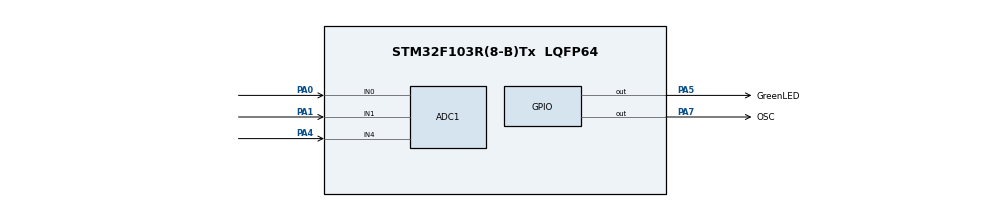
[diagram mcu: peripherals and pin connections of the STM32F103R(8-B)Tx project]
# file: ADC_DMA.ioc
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ADC1.Channel-0\#ChannelRegularConversion=ADC_CHANNEL_0
ADC1.Channel-1\#ChannelRegularConversion=ADC_CHANNEL_1
ADC1.Channel-2\#ChannelRegularConversion=ADC_CHANNEL_4
ADC1.ContinuousConvMode=ENABLE
ADC1.NbrOfConversion=3
ADC1.NbrOfConversionFlag=1
ADC1.Rank-0\#ChannelRegularConversion=1
ADC1.Rank-1\#ChannelRegularConversion=2
ADC1.Rank-2\#ChannelRegularConversion=3
ADC1.SamplingTime-0\#ChannelRegularConversion=ADC_SAMPLETIME_239CYCLES_5
ADC1.SamplingTime-1\#ChannelRegularConversion=ADC_SAMPLETIME_239CYCLES_5
ADC1.SamplingTime-2\#ChannelRegularConversion=ADC_SAMPLETIME_239CYCLES_5
ADC1.master=1
Dma.ADC1.0.Direction=DMA_PERIPH_TO_MEMORY
Dma.ADC1.0.Instance=DMA1_Channel1
Dma.ADC1.0.MemDataAlignment=DMA_MDATAALIGN_HALFWORD
Dma.ADC1.0.MemInc=DMA_MINC_ENABLE
Dma.ADC1.0.Mode=DMA_CIRCULAR
Dma.ADC1.0.PeriphDataAlignment=DMA_PDATAALIGN_HALFWORD
Dma.ADC1.0.PeriphInc=DMA_PINC_DISABLE
Dma.ADC1.0.Priority=DMA_PRIORITY_LOW
Dma.Request0=ADC1
Mcu.Family=STM32F1
Mcu.Name=STM32F103R(8-B)Tx
Mcu.Package=LQFP64
NVIC.DMA1_Channel1_IRQn=true\:0\:0\:false\:false\:true\:false\:true\:true
NVIC.PriorityGroup=NVIC_PRIORITYGROUP_4
PA0-WKUP.Signal=ADCx_IN0
PA1.Signal=ADCx_IN1
PA4.Signal=ADCx_IN4
PA5.GPIO_Label=GreenLED
PA5.Signal=GPIO_Output
PA7.GPIO_Label=OSC
PA7.Signal=GPIO_Output
ProjectManager.HeapSize=0x200
ProjectManager.StackSize=0x400
ProjectManager.TargetToolchain=MDK-ARM V5.32
RCC.APB1Freq_Value=8000000
RCC.APB2Freq_Value=8000000
SH.ADCx_IN0.0=ADC1_IN0,IN0
SH.ADCx_IN1.0=ADC1_IN1,IN1
SH.ADCx_IN4.0=ADC1_IN4,IN4
VP_SYS_VS_ND.Mode=No_Debug
board=custom

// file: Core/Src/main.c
/* USER CODE BEGIN Header */
/**
  ******************************************************************************
  * @file           : main.c
  * @brief          : Main program body
  ******************************************************************************
  * @attention
  *
  * Copyright (c) 2024 STMicroelectronics.
  * All rights reserved.
  *
  * This software is licensed under terms that can be found in the LICENSE file
  * in the root directory of this software component.
  * If no LICENSE file comes with this software, it is provided AS-IS.
  *
  ******************************************************************************
  */
/* USER CODE END Header */
#include "main.h"

ADC_HandleTypeDef hadc1;
DMA_HandleTypeDef hdma_adc1;

/* USER CODE BEGIN PV */

uint16_t AdcValueArray[3];

/* USER CODE END PV */

void SystemClock_Config(void);
static void MX_GPIO_Init(void);
static void MX_DMA_Init(void);
static void MX_ADC1_Init(void);

int main(void)
{

  /* MCU Configuration--------------------------------------------------------*/

  /* Reset of all peripherals, Initializes the Flash interface and the Systick. */
  HAL_Init();

  /* Configure the system clock */
  SystemClock_Config();

  /* Initialize all configured peripherals */
  MX_GPIO_Init();
  MX_DMA_Init();
  MX_ADC1_Init();
  /* USER CODE BEGIN 2 */

	HAL_ADC_Start_DMA(&hadc1, (uint32_t*) AdcValueArray, 3);

  /* USER CODE END 2 */

  /* Infinite loop */
  while (1)
  {

  }
}

void SystemClock_Config(void)
{
  RCC_OscInitTypeDef RCC_OscInitStruct = {0};
  RCC_ClkInitTypeDef RCC_ClkInitStruct = {0};
  RCC_PeriphCLKInitTypeDef PeriphClkInit = {0};

  /** Initializes the RCC Oscillators according to the specified parameters
  * in the RCC_OscInitTypeDef structure.
  */
  RCC_OscInitStruct.OscillatorType = RCC_OSCILLATORTYPE_HSI;
  RCC_OscInitStruct.HSIState = RCC_HSI_ON;
  RCC_OscInitStruct.HSICalibrationValue = RCC_HSICALIBRATION_DEFAULT;
  RCC_OscInitStruct.PLL.PLLState = RCC_PLL_NONE;
  if (HAL_RCC_OscConfig(&RCC_OscInitStruct) != HAL_OK)
  {
    Error_Handler();
  }

  /** Initializes the CPU, AHB and APB buses clocks
  */
  RCC_ClkInitStruct.ClockType = RCC_CLOCKTYPE_HCLK|RCC_CLOCKTYPE_SYSCLK
                              |RCC_CLOCKTYPE_PCLK1|RCC_CLOCKTYPE_PCLK2;
  RCC_ClkInitStruct.SYSCLKSource = RCC_SYSCLKSOURCE_HSI;
  RCC_ClkInitStruct.AHBCLKDivider = RCC_SYSCLK_DIV1;
  RCC_ClkInitStruct.APB1CLKDivider = RCC_HCLK_DIV1;
  RCC_ClkInitStruct.APB2CLKDivider = RCC_HCLK_DIV1;

  if (HAL_RCC_ClockConfig(&RCC_ClkInitStruct, FLASH_LATENCY_0) != HAL_OK)
  {
    Error_Handler();
  }
  PeriphClkInit.PeriphClockSelection = RCC_PERIPHCLK_ADC;
  PeriphClkInit.AdcClockSelection = RCC_ADCPCLK2_DIV2;
  if (HAL_RCCEx_PeriphCLKConfig(&PeriphClkInit) != HAL_OK)
  {
    Error_Handler();
  }
}

static void MX_ADC1_Init(void)
{

  ADC_ChannelConfTypeDef sConfig = {0};

  /** Common config
  */
  hadc1.Instance = ADC1;
  hadc1.Init.ScanConvMode = ADC_SCAN_ENABLE;
  hadc1.Init.ContinuousConvMode = ENABLE;
  hadc1.Init.DiscontinuousConvMode = DISABLE;
  hadc1.Init.ExternalTrigConv = ADC_SOFTWARE_START;
  hadc1.Init.DataAlign = ADC_DATAALIGN_RIGHT;
  hadc1.Init.NbrOfConversion = 3;
  if (HAL_ADC_Init(&hadc1) != HAL_OK)
  {
    Error_Handler();
  }

  /** Configure Regular Channel
  */
  sConfig.Channel = ADC_CHANNEL_0;
  sConfig.Rank = ADC_REGULAR_RANK_1;
  sConfig.SamplingTime = ADC_SAMPLETIME_239CYCLES_5;
  if (HAL_ADC_ConfigChannel(&hadc1, &sConfig) != HAL_OK)
  {
    Error_Handler();
  }

  /** Configure Regular Channel
  */
  sConfig.Channel = ADC_CHANNEL_1;
  sConfig.Rank = ADC_REGULAR_RANK_2;
  if (HAL_ADC_ConfigChannel(&hadc1, &sConfig) != HAL_OK)
  {
    Error_Handler();
  }

  /** Configure Regular Channel
  */
  sConfig.Channel = ADC_CHANNEL_4;
  sConfig.Rank = ADC_REGULAR_RANK_3;
  if (HAL_ADC_ConfigChannel(&hadc1, &sConfig) != HAL_OK)
  {
    Error_Handler();
  }

}

static void MX_DMA_Init(void)
{

  /* DMA controller clock enable */
  __HAL_RCC_DMA1_CLK_ENABLE();

  /* DMA interrupt init */
  /* DMA1_Channel1_IRQn interrupt configuration */
  HAL_NVIC_SetPriority(DMA1_Channel1_IRQn, 0, 0);
  HAL_NVIC_EnableIRQ(DMA1_Channel1_IRQn);

}

static void MX_GPIO_Init(void)
{
  GPIO_InitTypeDef GPIO_InitStruct = {0};

  /* GPIO Ports Clock Enable */
  __HAL_RCC_GPIOA_CLK_ENABLE();

  /*Configure GPIO pin Output Level */
  HAL_GPIO_WritePin(GPIOA, GreenLED_Pin|OSC_Pin, GPIO_PIN_RESET);

  /*Configure GPIO pins : GreenLED_Pin OSC_Pin */
  GPIO_InitStruct.Pin = GreenLED_Pin|OSC_Pin;
  GPIO_InitStruct.Mode = GPIO_MODE_OUTPUT_PP;
  GPIO_InitStruct.Pull = GPIO_NOPULL;
  GPIO_InitStruct.Speed = GPIO_SPEED_FREQ_LOW;
  HAL_GPIO_Init(GPIOA, &GPIO_InitStruct);

}

void Error_Handler(void)
{
  __disable_irq();
  while (1)
  {
  }
}
